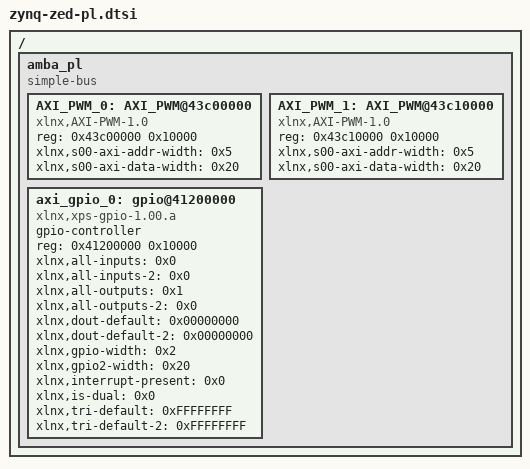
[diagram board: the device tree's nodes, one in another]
/*
 * CAUTION: This file is automatically generated by Xilinx.
 * Version:  
 * Today is: Tue Jan 08 11:47:35 2019
*/


/ {
	amba_pl: amba_pl {
		#address-cells = <1>;
		#size-cells = <1>;
		compatible = "simple-bus";
		ranges ;
		AXI_PWM_0: AXI_PWM@43c00000 {
			compatible = "xlnx,AXI-PWM-1.0";
			reg = <0x43c00000 0x10000>;
			xlnx,s00-axi-addr-width = <0x5>;
			xlnx,s00-axi-data-width = <0x20>;
		};
		AXI_PWM_1: AXI_PWM@43c10000 {
			compatible = "xlnx,AXI-PWM-1.0";
			reg = <0x43c10000 0x10000>;
			xlnx,s00-axi-addr-width = <0x5>;
			xlnx,s00-axi-data-width = <0x20>;
		};
		axi_gpio_0: gpio@41200000 {
			#gpio-cells = <2>;
			compatible = "xlnx,xps-gpio-1.00.a";
			gpio-controller ;
			reg = <0x41200000 0x10000>;
			xlnx,all-inputs = <0x0>;
			xlnx,all-inputs-2 = <0x0>;
			xlnx,all-outputs = <0x1>;
			xlnx,all-outputs-2 = <0x0>;
			xlnx,dout-default = <0x00000000>;
			xlnx,dout-default-2 = <0x00000000>;
			xlnx,gpio-width = <0x2>;
			xlnx,gpio2-width = <0x20>;
			xlnx,interrupt-present = <0x0>;
			xlnx,is-dual = <0x0>;
			xlnx,tri-default = <0xFFFFFFFF>;
			xlnx,tri-default-2 = <0xFFFFFFFF>;
		};
/*
		axi_iic_0: i2c@41600000 {
			#address-cells = <1>;
			#size-cells = <0>;
			clock-names = "ref_clk";
			clocks = "clkc 15";
			compatible = "xlnx,xps-iic-2.00.a";
			interrupt-parent = <&intc>;
			interrupts = <0 29 4>;
			reg = <0x41600000 0x10000>;
		};
		axi_iic_1: i2c@41610000 {
			#address-cells = <1>;
			#size-cells = <0>;
			clock-names = "ref_clk";
			clocks = "clkc 15";
			compatible = "xlnx,xps-iic-2.00.a";
			interrupt-parent = <&intc>;
			interrupts = <0 30 4>;
			reg = <0x41610000 0x10000>;
		};
		axi_iic_2: i2c@41620000 {
			#address-cells = <1>;
			#size-cells = <0>;
			clock-names = "ref_clk";
			clocks = "clkc 15";
			compatible = "xlnx,xps-iic-2.00.a";
			interrupt-parent = <&intc>;
			interrupts = <0 31 4>;
			reg = <0x41620000 0x10000>;
		};
		axi_quad_spi_0: axi_quad_spi@41e00000 {
			bits-per-word = <8>;
			compatible = "xlnx,xps-spi-2.00.a";
			fifo-size = <16>;
			interrupt-parent = <&intc>;
			interrupts = <0 32 1>;
			num-cs = <0x1>;
			reg = <0x41e00000 0x10000>;
			xlnx,num-ss-bits = <0x1>;
			xlnx,spi-mode = <0>;
		};
		axi_quad_spi_1: axi_quad_spi@41e10000 {
			bits-per-word = <8>;
			compatible = "xlnx,xps-spi-2.00.a";
			fifo-size = <16>;
			interrupt-parent = <&intc>;
			interrupts = <0 33 1>;
			num-cs = <0x1>;
			reg = <0x41e10000 0x10000>;
			xlnx,num-ss-bits = <0x1>;
			xlnx,spi-mode = <0>;
		};
 */
	};
};
